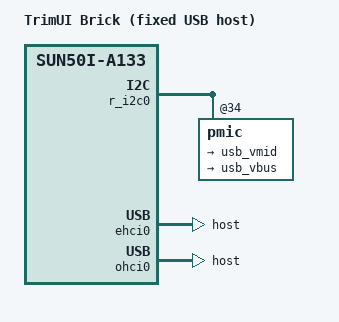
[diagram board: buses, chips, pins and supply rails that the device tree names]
// SPDX-License-Identifier: (GPL-2.0+ OR MIT)
/*
 * Opt-in fixed host role for the bottom port; the top port is always a host.
 * PH8 detects the OTG adapter; the AXP2202 supplies switched VBUS.
 * Requires the independent VMID/switch PMIC implementation (selector != 0).
 */
#include "sun50i-a133-trimui-brick.dts"

/ {
	model = "TrimUI Brick (fixed USB host)";
};

&r_i2c0 {
	pmic@34 {
		regulators {
			usb_vmid: vmid {
				regulator-name = "brick-usb-vmid";
			};
			usb_vbus: drivevbus {
				regulator-name = "brick-usb-vbus";
				vin-supply = <&usb_vmid>;
			};
		};
	};
};

&usb_otg {
	status = "disabled";
};

&usbphy {
	usb0_id_det-gpios = <&pio 7 8 GPIO_ACTIVE_HIGH>;
	usb0_vbus-supply = <&usb_vbus>;
};

&ehci0 {
	dr_mode = "host";
	status = "okay";
};

&ohci0 {
	dr_mode = "host";
	status = "okay";
};
